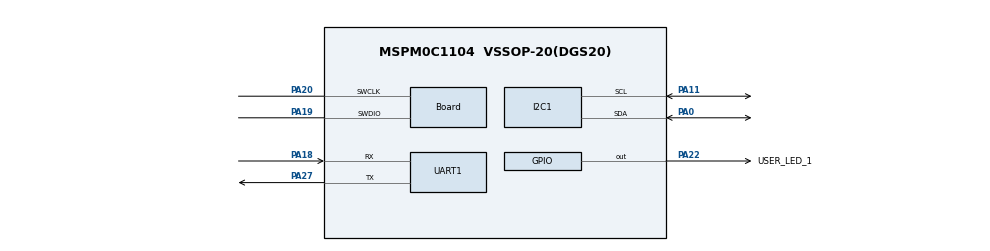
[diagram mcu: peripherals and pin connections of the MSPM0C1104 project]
//@cliArgs --device "MSPM0C110X" --package "VSSOP-20(DGS20)" --part "Default"
//@v2CliArgs --device "MSPM0C1104" --package "VSSOP-20(DGS20)"
// @cliArgs --board /ti/boards/LP_MSPM0C1104 --rtos nortos

/**
 * Import the modules used in this configuration.
 */
const Board  = scripting.addModule("/ti/driverlib/Board");
const GPIO   = scripting.addModule("/ti/driverlib/GPIO", {}, false);
const GPIO1  = GPIO.addInstance();
const I2C    = scripting.addModule("/ti/driverlib/I2C", {}, false);
const I2C1   = I2C.addInstance();
const SYSCTL = scripting.addModule("/ti/driverlib/SYSCTL");
const UART   = scripting.addModule("/ti/driverlib/UART", {}, false);
const UART1  = UART.addInstance();

/**
 * Write custom configuration values to the imported modules.
 */
Board.peripheral.$assign          = "DEBUGSS";
Board.peripheral.swclkPin.$assign = "PA20";
Board.peripheral.swdioPin.$assign = "PA19";

GPIO1.$name                         = "GPIO_LEDS";
GPIO1.associatedPins[0].$name       = "USER_LED_1";
GPIO1.associatedPins[0].assignedPin = "22";
GPIO1.associatedPins[0].pin.$assign = "PA22";

I2C1.$name                     = "I2C_0";
I2C1.basicEnableController     = true;
I2C1.peripheral.$assign        = "I2C0";
I2C1.peripheral.sdaPin.$assign = "PA0";
I2C1.peripheral.sclPin.$assign = "PA11";

SYSCTL.peripheral.$assign = "SYSCTL";

UART1.$name                    = "UART_0";
UART1.profile                  = "CONFIG_PROFILE_2";
UART1.peripheral.$assign       = "UART0";
UART1.peripheral.rxPin.$assign = "PA18";
UART1.peripheral.txPin.$assign = "PA27";
